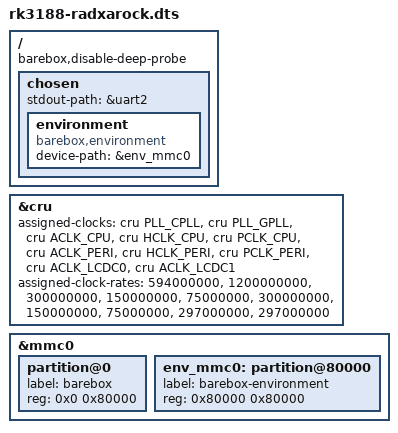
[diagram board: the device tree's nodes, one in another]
/*
 * Copyright (c) 2013 Heiko Stuebner <heiko@sntech.de>
 *
 * This program is free software; you can redistribute it and/or modify
 * it under the terms of the GNU General Public License as published by
 * the Free Software Foundation; either version 2 of the License, or
 * (at your option) any later version.
 *
 * This program is distributed in the hope that it will be useful,
 * but WITHOUT ANY WARRANTY; without even the implied warranty of
 * MERCHANTABILITY or FITNESS FOR A PARTICULAR PURPOSE.  See the
 * GNU General Public License for more details.
 */

#include <arm/rockchip/rk3188-radxarock.dts>

/ {
	barebox,disable-deep-probe;

	chosen {
		stdout-path = &uart2;

		environment {
			compatible = "barebox,environment";
			device-path = &env_mmc0;
		};
	};
};

&cru {
	assigned-clocks = <&cru PLL_CPLL>, <&cru PLL_GPLL>,
		<&cru ACLK_CPU>, <&cru HCLK_CPU>,
		<&cru PCLK_CPU>, <&cru ACLK_PERI>,
		<&cru HCLK_PERI>, <&cru PCLK_PERI>,
		<&cru ACLK_LCDC0>, <&cru ACLK_LCDC1>;
	assigned-clock-rates = <594000000>, <1200000000>,
			       <300000000>, <150000000>,
			       <75000000>, <300000000>,
			       <150000000>, <75000000>,
			       <297000000>, <297000000>;
};

&mmc0 {
	#address-cells = <1>;
	#size-cells = <1>;

	partition@0 {
		label = "barebox";
		reg = <0x0 0x80000>;
	};

	env_mmc0: partition@80000 {
		label = "barebox-environment";
		reg = <0x80000 0x80000>;
	};
};
